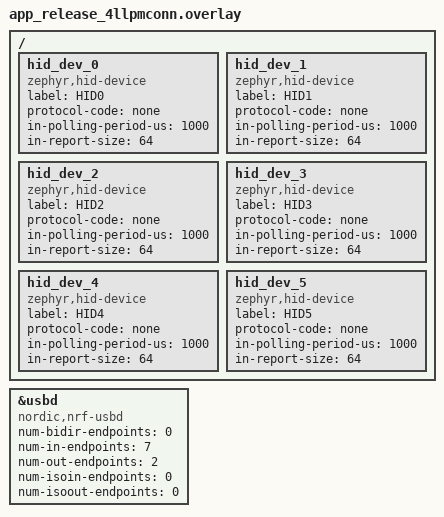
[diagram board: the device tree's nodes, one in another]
/*
 * Copyright (c) 2024 Nordic Semiconductor ASA
 *
 * SPDX-License-Identifier: LicenseRef-Nordic-5-Clause
 */

#include "app_common.dtsi"

/ {
	/* Configure DTS nodes used for USB next HID support. */
	hid_dev_0: hid_dev_0 {
		compatible = "zephyr,hid-device";
		label = "HID0";
		protocol-code = "none";
		in-polling-period-us = <1000>;
		in-report-size = <64>;
	};

	hid_dev_1: hid_dev_1 {
		compatible = "zephyr,hid-device";
		label = "HID1";
		protocol-code = "none";
		in-polling-period-us = <1000>;
		in-report-size = <64>;
	};

	hid_dev_2: hid_dev_2 {
		compatible = "zephyr,hid-device";
		label = "HID2";
		protocol-code = "none";
		in-polling-period-us = <1000>;
		in-report-size = <64>;
	};

	hid_dev_3: hid_dev_3 {
		compatible = "zephyr,hid-device";
		label = "HID3";
		protocol-code = "none";
		in-polling-period-us = <1000>;
		in-report-size = <64>;
	};

	hid_dev_4: hid_dev_4 {
		compatible = "zephyr,hid-device";
		label = "HID4";
		protocol-code = "none";
		in-polling-period-us = <1000>;
		in-report-size = <64>;
	};

	hid_dev_5: hid_dev_5 {
		compatible = "zephyr,hid-device";
		label = "HID5";
		protocol-code = "none";
		in-polling-period-us = <1000>;
		in-report-size = <64>;
	};
};

&usbd {
	compatible = "nordic,nrf-usbd";
	status = "okay";
	num-bidir-endpoints = <0>;
	num-in-endpoints = <7>;
	num-out-endpoints = <2>;
	num-isoin-endpoints = <0>;
	num-isoout-endpoints = <0>;
};
